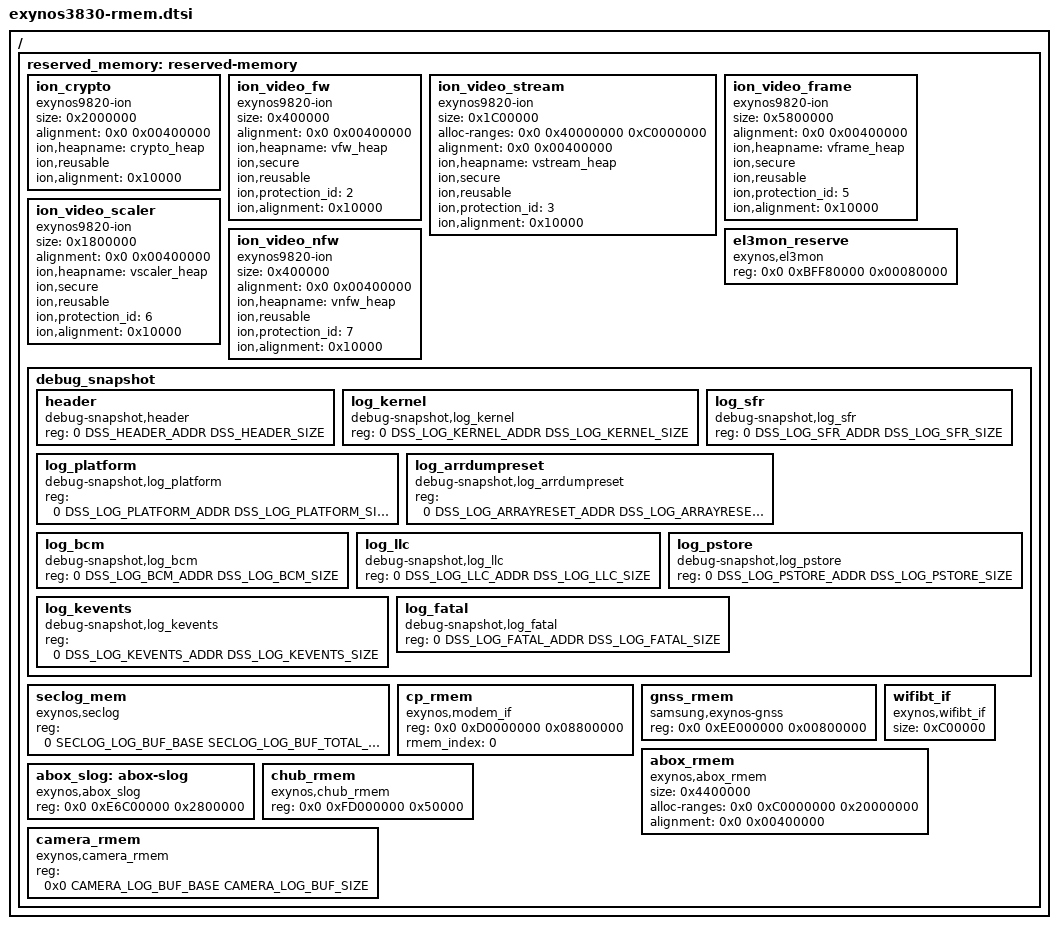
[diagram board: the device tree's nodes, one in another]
/*
 * SAMSUNG EXYNOS device tree source for reserved-memory
 *
 * Copyright (c) 2015 Samsung Electronics Co., Ltd.
 *		http://www.samsung.com
 *
 * This program is free software; you can redistribute it and/or modify
 * it under the terms of the GNU General Public License version 2 as
 * published by the Free Software Foundation.
 */

#include <dt-bindings/soc/samsung/debug-snapshot-def.h>
#include <dt-bindings/soc/samsung/exynos3830-seclog.h>
#include <dt-bindings/camera/exynos_is_dt.h>

/ {
	reserved_memory: reserved-memory {
		#address-cells = <2>;
		#size-cells = <1>;
		ranges;

		ion_crypto {
			compatible = "exynos9820-ion";
			size = <0x2000000>;
			alignment = <0x0 0x00400000>;
			ion,heapname = "crypto_heap";
			ion,reusable;
			ion,alignment = <0x10000>;
		};

		ion_video_fw {
			compatible = "exynos9820-ion";
			size = <0x400000>;
			alignment = <0x0 0x00400000>;
			ion,heapname = "vfw_heap";
			ion,secure;
			ion,reusable;
			ion,protection_id = <2>;
			ion,alignment = <0x10000>;
		};

		ion_video_stream {
			compatible = "exynos9820-ion";
			size = <0x1C00000>;
			alloc-ranges = <0x0 0x40000000 0xC0000000>;
			alignment = <0x0 0x00400000>;
			ion,heapname = "vstream_heap";
			ion,secure;
			ion,reusable;
			ion,protection_id = <3>;
			ion,alignment = <0x10000>;
		};

		ion_video_frame {
			compatible = "exynos9820-ion";
			size = <0x5800000>;
			alignment = <0x0 0x00400000>;
			ion,heapname = "vframe_heap";
			ion,secure;
			ion,reusable;
			ion,protection_id = <5>;
			ion,alignment = <0x10000>;
		};

		ion_video_scaler {
			compatible = "exynos9820-ion";
			size = <0x1800000>;
			alignment = <0x0 0x00400000>;
			ion,heapname = "vscaler_heap";
			ion,secure;
			ion,reusable;
			ion,protection_id = <6>;
			ion,alignment = <0x10000>;
		};

		ion_video_nfw {
			compatible = "exynos9820-ion";
			size = <0x400000>;
			alignment = <0x0 0x00400000>;
			ion,heapname = "vnfw_heap";
			ion,reusable;
			ion,protection_id = <7>;
			ion,alignment = <0x10000>;
		};

		el3mon_reserve {
			compatible = "exynos,el3mon";
			reg = <0x0 0xBFF80000 0x00080000>;
		};

		debug_snapshot {
			#address-cells = <2>;
			#size-cells = <1>;

			header {
				compatible = "debug-snapshot,header";
				reg = <0 DSS_HEADER_ADDR DSS_HEADER_SIZE>;
			};
			log_kernel {
				compatible = "debug-snapshot,log_kernel";
				reg = <0 DSS_LOG_KERNEL_ADDR DSS_LOG_KERNEL_SIZE>;
			};
			log_platform {
				compatible = "debug-snapshot,log_platform";
				reg = <0 DSS_LOG_PLATFORM_ADDR DSS_LOG_PLATFORM_SIZE>;
			};
			log_sfr {
				compatible = "debug-snapshot,log_sfr";
				reg = <0 DSS_LOG_SFR_ADDR DSS_LOG_SFR_SIZE>;
			};
			log_arrdumpreset {
				compatible = "debug-snapshot,log_arrdumpreset";
				reg = <0 DSS_LOG_ARRAYRESET_ADDR DSS_LOG_ARRAYRESET_SIZE>;
			};
			log_bcm {
				compatible = "debug-snapshot,log_bcm";
				reg = <0 DSS_LOG_BCM_ADDR DSS_LOG_BCM_SIZE>;
			};
			log_llc {
				compatible = "debug-snapshot,log_llc";
				reg = <0 DSS_LOG_LLC_ADDR DSS_LOG_LLC_SIZE>;
			};
			log_pstore {
				compatible = "debug-snapshot,log_pstore";
				reg = <0 DSS_LOG_PSTORE_ADDR DSS_LOG_PSTORE_SIZE>;
			};
			log_kevents {
				compatible = "debug-snapshot,log_kevents";
				reg = <0 DSS_LOG_KEVENTS_ADDR DSS_LOG_KEVENTS_SIZE>;
			};
			log_fatal {
				compatible = "debug-snapshot,log_fatal";
				reg = <0 DSS_LOG_FATAL_ADDR DSS_LOG_FATAL_SIZE>;
			};
		};

		seclog_mem {
			compatible = "exynos,seclog";
			reg = <0 SECLOG_LOG_BUF_BASE SECLOG_LOG_BUF_TOTAL_SIZE>;
		};

		cp_rmem {
			compatible = "exynos,modem_if";
			reg = <0x0 0xD0000000 0x08800000>;
			rmem_index = <0>;
		};

		gnss_rmem: gnss_rmem {
			compatible = "samsung,exynos-gnss";
			reg = <0x0 0xEE000000 0x00800000>;
		};

		wifibt_if {
			compatible = "exynos,wifibt_if";
			size = <0xC00000>; /* 12MB */
		};

		abox_rmem: abox_rmem {
			compatible = "exynos,abox_rmem";
			size = <0x4400000>;
			alloc-ranges = <0x0 0xC0000000 0x20000000>;
			alignment = <0x0 0x00400000>;
		};

		abox_slog: abox-slog {
			compatible = "exynos,abox_slog";
			/* linear area for cp call */
			reg = <0x0 0xE6C00000 0x2800000>;
		};

		chub_rmem: chub_rmem {
			compatible = "exynos,chub_rmem";
			/* To dump SHUB SRAM out upon shub firmware crash */
			reg = <0x0 0xFD000000 0x50000>;
		};

		camera_rmem: camera_rmem {
			compatible = "exynos,camera_rmem";
			reg = <0x0 CAMERA_LOG_BUF_BASE CAMERA_LOG_BUF_SIZE>;
		};
	};
};
